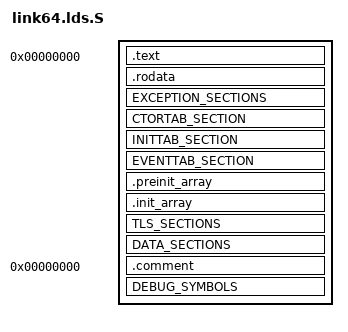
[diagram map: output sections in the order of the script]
/* SPDX-License-Identifier: BSD-2-Clause */
/*
 * Redistribution and use in source and binary forms, with or without
 * modification, are permitted provided that the following conditions
 * are met:
 * 1. Redistributions of source code must retain the above copyright
 *    notice, this list of conditions and the following disclaimer.
 * 2. Redistributions in binary form must reproduce the above copyright
 *    notice, this list of conditions and the following disclaimer in the
 *    documentation and/or other materials provided with the distribution.
 *
 * THIS SOFTWARE IS PROVIDED BY AUTHOR AND CONTRIBUTORS ``AS IS'' AND
 * ANY EXPRESS OR IMPLIED WARRANTIES, INCLUDING, BUT NOT LIMITED TO, THE
 * IMPLIED WARRANTIES OF MERCHANTABILITY AND FITNESS FOR A PARTICULAR PURPOSE
 * ARE DISCLAIMED.  IN NO EVENT SHALL AUTHOR OR CONTRIBUTORS BE LIABLE
 * FOR ANY DIRECT, INDIRECT, INCIDENTAL, SPECIAL, EXEMPLARY, OR CONSEQUENTIAL
 * DAMAGES (INCLUDING, BUT NOT LIMITED TO, PROCUREMENT OF SUBSTITUTE GOODS
 * OR SERVICES; LOSS OF USE, DATA, OR PROFITS; OR BUSINESS INTERRUPTION)
 * HOWEVER CAUSED AND ON ANY THEORY OF LIABILITY, WHETHER IN CONTRACT, STRICT
 * LIABILITY, OR TORT (INCLUDING NEGLIGENCE OR OTHERWISE) ARISING IN ANY WAY
 * OUT OF THE USE OF THIS SOFTWARE, EVEN IF ADVISED OF THE POSSIBILITY OF
 * SUCH DAMAGE.
 */
/* Taken from Mini-OS */

#include <uk/arch/limits.h> /* for __PAGE_SIZE */
#include <uk/plat/common/common.lds.h>

OUTPUT_FORMAT("elf64-x86-64")
OUTPUT_ARCH(i386:x86-64)

PHDRS
{
	text PT_LOAD FLAGS(PHDRS_PF_RX);
	rodata PT_LOAD FLAGS(PHDRS_PF_R);
	data PT_LOAD;
	tls PT_TLS;
	tls_load PT_LOAD;
	stack PT_GNU_STACK FLAGS(PHDRS_PF_RW);
}

ENTRY(_libxenplat_start)
SECTIONS
{
	. = 0x0;

	_base_addr = .;		/* Symbol to represent the load base address */

	_text = .;			/* Text and read-only data */
	.text : {
		*(.text.boot)
		*(.text)
		*(.gnu.warning)
	} :text = 0x2000

	_etext = .;			/* End of text section */

	_rodata = .;
	.rodata : {
		*(.rodata)
		*(.rodata.*)
	} :rodata
	. = ALIGN(__PAGE_SIZE);
	_erodata = .;

	EXCEPTION_SECTIONS

	CTORTAB_SECTION

	INITTAB_SECTION

	EVENTTAB_SECTION

	. = ALIGN(0x8);
	_ctors = .;
	.preinit_array : {
		PROVIDE_HIDDEN (__preinit_array_start = .);
		KEEP (*(.preinit_array))
		PROVIDE_HIDDEN (__preinit_array_end = .);
	}

	. = ALIGN(0x8);
	.init_array : {
		PROVIDE_HIDDEN (__init_array_start = .);
		KEEP (*(SORT_BY_INIT_PRIORITY(.init_array.*) SORT_BY_INIT_PRIORITY(.ctors.*)))
		KEEP (*(.init_array .ctors))
		PROVIDE_HIDDEN (__init_array_end = .);
	}
	. = ALIGN(__PAGE_SIZE);
	_ectors = .;

	TLS_SECTIONS

	DATA_SECTIONS

	_end = .;

	/* Sections to be discarded */
	/* TODO: Revisit when we have a solution for discarded sections
	/DISCARD/ : {
		*(.text.exit)
		*(.data.exit)
		*(.exitcall.exit)
	}
	*/

	.comment 0 : { *(.comment) }
	DEBUG_SYMBOLS

	DISCARDS
}
